# MCSPI2 register map
Vendor: Texas Instruments
Peripheral module from a debugger description file (folder omap34xx).
Registers are 32-bit, read-write, reset 0x0 unless marked. A register's access mark holds for its fields unless they carry their own. Offsets are as the file gives them; lines under a group give offsets from that group; [hi:lo] are bit positions; {n}, {i} and the like mark numbered series; 'fields as' and 'values as' point back to an identical list; <NAME> marks a mode.

## MCSPI2
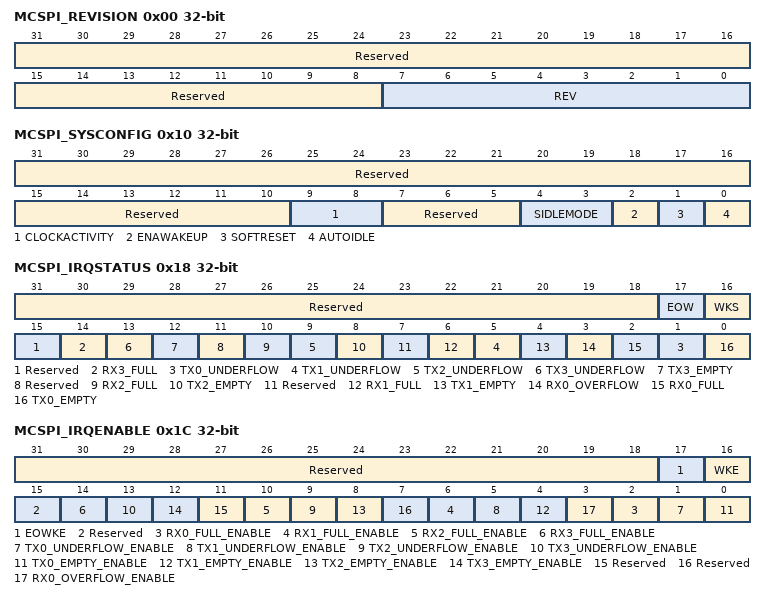
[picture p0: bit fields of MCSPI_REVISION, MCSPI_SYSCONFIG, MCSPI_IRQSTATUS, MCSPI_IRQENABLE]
0x00 MCSPI_REVISION ro (reset mask 0xFFFFFF00) — This register contains the hard coded RTL revision number.
  [31:8] Reserved — Reads returns 0
  [7:0] REV — IP revision[7:4] . Major revision . [3:0] . Minor revision . Example: 0x10 for 1.0, 0x21 for 2.1 .
0x10 MCSPI_SYSCONFIG — This register allows control of various parameters of the module interface. It is not sensitive to software reset.
  [31:10] Reserved — Reads returns 0
  [9:8] CLOCKACTIVITY — Clocks activity during wake up mode period
    0=Interface and Functional clocks may be switched off; 1=Interface clock is maintained. Functional clock may be switched off.; 2=Functional clock is maintained. Interface clock may be switched off.; 3=Interface and Functional clocks are maintained
  [7:5] Reserved — Reads returns 0
  [4:3] SIDLEMODE — Power management
    0=If an idle request is detected, the McSPI acknowledges it unconditionally and goes in Inactive mode. Interrupt, DMA requests and wake up lines are unconditionally de-asserted and the module wake-up capability is deactivated even if the bit[ ENAWAKEUP] is set.; 1=If an idle request is detected, the request is ignored and the module does not switch to wake up mode and keeps on behaving normally; 2=If an idle request is detected, the module will switch to wake up mode based on its internal activity and the wake up capability can be used if the bit[ENAWAKEUP] is set; 3=Reserved - do not use
  [2] ENAWAKEUP — Wake-up feature control
    0=Wake-up capability disabled; 1=Wake-up capability enabled
  [1] SOFTRESET — Software reset. Read always returns 0.
    0=Normal mode; 1=Trigger a module reset. This bit is automatically reset by hardware.
  [0] AUTOIDLE — Internal interface Clock gating strategy
    0=interface clock is free-running; 1=Automatic interface clock gating strategy is applied, based on the module interface activity
0x14 MCSPI_SYSSTATUS ro — This register provides status information about the module excluding the interrupt status information
  [0] RESETDONE — Internal Reset Monitoring
    0=Internal module reset is on-going; 1=Reset completed
0x18 MCSPI_IRQSTATUS — The interrupt status regroups all the status of the module internal events that can generate an interrupt
  [31:18] Reserved — Reads returns 0
  [17] EOW — End of word count event when a channel is enabled using the FIFO buffer and the channel had sent the number of SPI word defined by MCSPI_XFERLEVEL[31:16] WCNT bit field.
    0=EOW_0_w (Event status bit unchanged.); 0=EOW_0_r (Event false.); 1=EOW_1_w (Event status bit is reset.); 1=EOW_1_r (Event is pending.)
  [16] WKS — Wake-up event in slave mode when an active control signal is detected on the spim_csx line programmed in theMCSPI_CHxCONF[SPIENSLV] field (where x=0 only)
    0=WKS_0_w (Event status bit unchanged); 0=WKS_0_r (Event false); 1=WKS_1_w (Event status bit is reset.); 1=WKS_1_r (Event is pending.)
  [15] Reserved — Reads returns 0.
  [14] RX3_FULL — MCSPI_RX3 register is full (only when channel 3 is enabled)
    0=RX3_FULL_0_w (Event status bit unchanged); 0=RX3_FULL_0_r (Event false); 1=RX3_FULL_1_w (Event status bit is reset.); 1=RX3_FULL_1_r (Event is pending.)
  [4n+1] TX{n}_UNDERFLOW (n=0..3) — MCSPI_TX{n} register underflow (only when channel {n} is enabled)
    0=TX{n}_UNDERFLOW_0_w (Event status bit unchanged); 0=TX{n}_UNDERFLOW_0_r (Event false); 1=TX{n}_UNDERFLOW_1_w (Event status bit is reset.); 1=TX{n}_UNDERFLOW_1_r (Event is pending.)
  [12] TX3_EMPTY — MCSPI_TX3 register is empty (only when channel 3 is enabled)
    0=TX3_EMPTY_0_w (Event status bit unchanged); 0=TX3_EMPTY_0_r (Event false); 1=TX3_EMPTY_1_w (Event status bit is reset.); 1=TX3_EMPTY_1_r (Event is pending.)
  [11] Reserved — Read returns 0.
  [10] RX2_FULL — MCSPI_RX2 register full (only when channel 2 is enabled)
    0=RX2_FULL_0_w (Event status bit unchanged); 0=RX2_FULL_0_r (Event false); 1=RX2_FULL_1_w (Event status bit is reset.); 1=RX2_FULL_1_r (Event is pending.)
  [8] TX2_EMPTY — MCSPI_TX2 register empty (only when channel 2 is enabled)
    0=TX2_EMPTY_0_w (Event status bit unchanged); 0=TX2_EMPTY_0_r (Event false); 1=TX2_EMPTY_1_w (Event status bit is reset.); 1=TX2_EMPTY_1_r (Event is pending.)
  [7] Reserved — Read returns 0.
  [6] RX1_FULL — MCSPI_RX1 register full (only when channel 1 is enabled)
    0=RX1_FULL_0_w (Event status bit unchanged); 0=RX1_FULL_0_r (Event false); 1=RX1_FULL_1_w (Event status bit is reset.); 1=RX1_FULL_1_r (Event is pending.)
  [4] TX1_EMPTY — MCSPI_TX1 register empty (only when channel 1 is enabled)
    0=TX1_EMPTY_0_w (Event status bit unchanged); 0=TX1_EMPTY_0_r (Event false); 1=TX1_EMPTY_1_w (Event status bit is reset.); 1=TX1_EMPTY_1_r (Event is pending.)
  [3] RX0_OVERFLOW — MCSPI_RX0 register overflow (only in slave mode)
    0=RX0_OVERFLOW_0_w (Event status bit unchanged); 0=RX0_OVERFLOW_0_r (Event false); 1=RX0_OVERFLOW_1_w (Event status bit is reset.); 1=RX0_OVERFLOW_1_r (Event is pending.)
  [2] RX0_FULL — MCSPI_RX0 register full (only when channel 0 is enabled)
    0=RX0_FULL_0_w (Event status bit unchanged); 0=RX0_FULL_0_r (Event false); 1=RX0_FULL_1_w (Event status bit is reset.); 1=RX0_FULL_1_r (Event is pending.)
  [0] TX0_EMPTY — MCSPI_TX0 register empty (only when channel 0 is enabled)
    0=TX0_EMPTY_0_w (Event status bit unchanged); 0=TX0_EMPTY_0_r (Event false); 1=TX0_EMPTY_1_w (Event status bit is reset.); 1=TX0_EMPTY_1_r (Event is pending.)
0x1C MCSPI_IRQENABLE — This register allows to enable/disable the module internal sources of interrupt, on an event-by-event basis.
  [31:18] Reserved — Reads return 0
  [17] EOWKE — End of Word count Interrupt Enable.
    0=Interrupt disabled; 1=Interrupt enabled
  [16] WKE — Wake-up event interrupt enable in slave mode when an active control signal is detected on the spim_csx line programmed in theMCSPI_CHxCONF[SPIENSLV] field (where x=0 only)
    0=Interrupt disabled; 1=Interrupt enabled
  [15] Reserved — Read returns 0.
  [4n+2] RX{n}_FULL_ENABLE (n=0..3) — MCSPI_RX{n} register full interrupt enable (channel {n})
    0=Interrupt disabled; 1=Interrupt enabled
  [4n+1] TX{n}_UNDERFLOW_ENABLE (n=0..3) — MCSPI_TX{n} register underflow interrupt enable (channel {n})
    0=Interrupt disabled; 1=Interrupt enabled
  [4n] TX{n}_EMPTY_ENABLE (n=0..3) — MCSPI_TX{n} register empty interrupt enable (channel {n})
    0=Interrupt disabled; 1=Interrupt enabled
  [11] Reserved — Read returns 0.
  [7] Reserved — Read returns 0.
  [3] RX0_OVERFLOW_ENABLE — MCSPI_RX0 register overflow interrupt enable (channel 0)
    0=Interrupt disabled; 1=Interrupt enabled
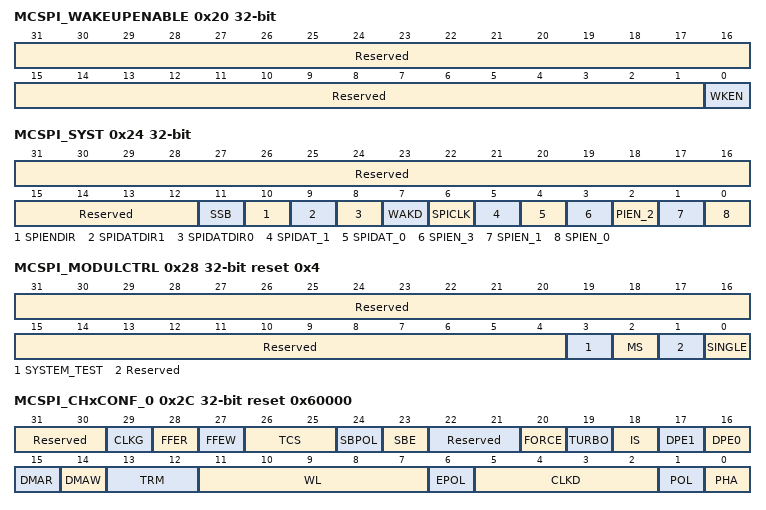
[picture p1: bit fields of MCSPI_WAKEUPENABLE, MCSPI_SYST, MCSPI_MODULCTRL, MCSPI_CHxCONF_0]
0x20 MCSPI_WAKEUPENABLE — The wake-up enable register allows to enable/disable the module internal sources of wake-up on event-by-event basis.
  [31:1] Reserved — Reads return 0
  [0] WKEN — Wake-up functionality in slave mode when an active control signal is detected on the spim_cs line programmed in the fieldMCSPI_CHxCONF[SPIENSLV]
    0=The event is not allowed to wake-up the system, even if the global control bit MCSPI_SYSCONF[ENAWAKEUP] is set; 1=The event is allowed to wake-up the system if the global control bit MCSPI_SYSCONF[ENAWAKEUP] is set
0x24 MCSPI_SYST — This register is used to check the correctness of the system interconnect either internally to peripheral bus, or externally to device IO pads, when the module is configured in system test (SYSTEST) mode.
  [31:12] Reserved — Reads returns 0
  [11] SSB — Set status bitThis bit must be cleared prior attempting to clear a status bit of the MCSPI_ IRQSTATUS register. . Writing 1 into this bit sets to 1 all status bits contained in the register. .
    0=No action. Writing 0 does not clear already set status bits;; 1=Force to 1 all status bits of MCSPI_ IRQSTATUS register
  [10] SPIENDIR — Set the direction of the spim_cs lines and spim_clk line
    0=Output (as in master mode); 1=Input (as in slave mode)
  [9] SPIDATDIR1 — Set the direction of the SPIDAT[1] (spim_simo)
    0=Output; 1=Input
  [8] SPIDATDIR0 — Set the direction of the SPIDAT[0] (spim_somi)
    0=Output; 1=Input
  [7] WAKD — SWAKEUP output (signal data value of internal signal to system).The signal is driven high or low according to the value written into this register bit. .
    0=The pin is driven low; 1=The pin is driven high
  [6] SPICLK — spim_clk line (signal data value)If[SPIENDIR] = 1 (input mode direction), this bit returns the value on the spim_clk line (high or low) and a write into this bit has no effect. . If[SPIENDIR] = 0 (output mode direction), the spim_clk line is driven high or low according to the value written into this register. .
  [5] SPIDAT_1 — spim_somi line (signal data value)If[SPIDATDIR1] = 0 (output mode direction), the spim_somi line is driven high or low according to the value written into this register. . If[SPIDATDIR1] = 1 (input mode direction), this bit returns the value on the spim_somi line (high or low) and a write into this bit has no effect. .
  [4] SPIDAT_0 — spim_simo line (signal data value)If[SPIDATDIR0] = 0 (output mode direction), the spim_simo line is driven high or low according to the value written into this register. . If[SPIDATDIR0] = 1 (input mode direction), this bit returns the value on the spim_simo line (high or low) and a write into this bit has no effect. .
  [3] SPIEN_3 — spim_cs3 line (signal data value)If[SPIENDIR] = 0 (output mode direction), the spim_cs3 line is driven high or low according to the value written into this register. . If[SPIENDIR] = 1 (input mode direction), this bit returns the value on the spim_cs3 line (high or low) and a write into this bit has no effect. .
  [2] PIEN_2 — spim_cs2 line (signal data value)If[SPIENDIR] = 0 (output mode direction), the spim_cs2 line is driven high or low according to the value written into this register. . If[SPIENDIR] = 1 (input mode direction), this bit returns the value on the spim_cs2 line (high or low) and a write into this bit has no effect. .
  [1] SPIEN_1 — spim_cs1 line (signal data value)If[SPIENDIR] = 0 (output mode direction), the spim_cs1 line is driven high or low according to the value written into this register. . If[SPIENDIR] = 1 (input mode direction), this bit returns the value on the spim_cs1 line (high or low) and a write into this bit has no effect. .
  [0] SPIEN_0 — spim_cs0 line (signal data value)If[SPIENDIR] = 0 (output mode direction), the spim_cs0 line is driven high or low according to the value written into this register. . If[SPIENDIR] = 1 (input mode direction), this bit returns the value on the spim_cs0 line (high or low) and a write into this bit has no effect. .
0x28 MCSPI_MODULCTRL reset 0x4 — This register is dedicated to the configuration of the serial port interface.
  [31:4] Reserved — Reads returns 0
  [3] SYSTEM_TEST — Enables the system test mode
    0=Functional mode; 1=System test mode (SYSTEST)
  [2] MS — Master/ Slave
    0=Master - The module generates the spim_clk and spim_cs for channel x; 1=Slave - The module receive
  [1] Reserved — (returns 0 after writing 0) (returns 1 after writing 1)
  [0] SINGLE — Single forced channel/multichannel (master mode only)
    0=One or more channels will be used in master mode with automatic chip-select generation; 1=Only one channel will be used in master mode and the chip-select is driven by the[20] FORCE bit. This bit must be set in force spim_cs mode.
0x2C MCSPI_CHxCONF_0 reset 0x60000 — This register is dedicated to the configuration of the channel x.
  [31:30] Reserved — Read returns 0s.
  [29] CLKG — Clock divider granularity. This register defines the granularity of channel clock divider: power of two or one clock cycle granularity. When this bit is set, theMCSPI_CHxCTRL[15:8] EXTCLK bit field must be configured to reach a maximum of 4096 clock divider ratio. Then the clock divider ratio is a concatenation of MCSPI_CHxCONF[5:2] CLKD and EXTCLK values.
    0=Clock granularity of power of two; 1=One clock cycle ganularity
  [28] FFER — FIFO enabled for Receive. Only one channel can have this bit field set.
    0=The buffer is not used to Receive data; 1=The buffer is used to Receive data
  [27] FFEW — FIFO enabled for Transmit. Only one channel can have this bit field set.
    0=The buffer is not used to Transmit data; 1=The buffer is used to Transmit data
  [26:25] TCS — Chip select time controlDefines the number of interface clock cycles between CS toggling and first (or last) edge of SPI clock. .
    0=0.5 clock cycle; 1=1.5 clock cycles; 2=2.5 clock cycles; 3=3.5 clock cycles
  [24] SBPOL — Start bit polarity
    0=Start bit polarity is held to 0 during SPI transfer; 1=Start bit polarity is held to 1 during SPI transfer
  [23] SBE — Start bit enable for SPI transfer
    0=Default SPI transfer length as specified by WL bit field; 1=Start bit D/CX added before SPI transfer. Polarity is defined by[SBPOL].
  [22:21] Reserved — Write the reset value. Read returns the reset value.
  [20] FORCE — Manual spim_csx assertion to keep spim_csx for channel x active between SPI words (single channel master mode only). TheMCSPI_MODULCTRL[0] SINGLE bit must bit set to 1.
    0=Writing 0 into this bit drives the spin_csx line low for channel x when [6] EPOL = 0, and drives it high when [6] EPOL = 1; 1=Writing 1 into this bit drives the spim_csx line high for channel x when[E6] EPOL = 0, and drives it low when [6] EPOL = 1
  [19] TURBO — Turbo mode
    0=Turbo is deactivated (recommended for single SPI word transfer); 1=Turbo is activated to maximize the throughput for multi-SPI word transfers
  [18] IS — Input select
    0=Data Line 0 (spim_somi) selected for reception; 1=Data Line 1 (spim_simo) selected for reception
  [17] DPE1 — Transmission enable for data line 1 (spim_simo)
    0=Data Line 1 (spim_simo) selected for transmission; 1=No transmission on data Line 1 (spim_simo)
  [16] DPE0 — Transmission enable for data line 0 (spim_somi)
    0=Data Line 0 (spim_somi) selected for transmission; 1=No transmission on data Line 0 (spim_somi)
  [15] DMAR — DMA Read requestThe DMA Read request line is asserted when the channel is enabled and a new data is available in the receive register of the channel. . The DMA Read request line is deasserted on read completion of the receive register of the channel. .
    0=DMA read request disabled; 1=DMA read request enabled
  [14] DMAW — DMA Write request.The DMA write request line is asserted when the channel is enabled and the register of the channel is empty. . The DMA write request line is deasserted on load completion of the register of the channel. .
    0=DMA write request disabled; 1=DMA write request enabled
  [13:12] TRM — Transmit/receive modes
    0=Transmit and receive mode; 1=Receive-only mode; 2=Transmit-only mode
  [11:7] WL — SPI word length
    {v}=The SPI word is {v+1}-bit long (v=3..31)
  [6] EPOL — spim_csx polarity for channel x
    0=spim_csx is held high during the active state; 1=spim_csx is held low during the active state
  [5:2] CLKD — Frequency divider for spim_clk (for master device only)
    0=1; 1=2; 2=4; 3=8; 4=16; 5=32; 6=64; 7=128; 8=256; 9=512; 10=1024; 11=2048; 12=4096; 13=8192; 14=16384; 15=32768
  [1] POL — spim_clk polarity
    0=spim_clk is held high during the active state; 1=spim_clk is held low during the active state
  [0] PHA — spim_clk phase
    0=Data are latched on odd-numbered edges of spim_clk; 1=Data are latched on even-numbered edges of spim_clk
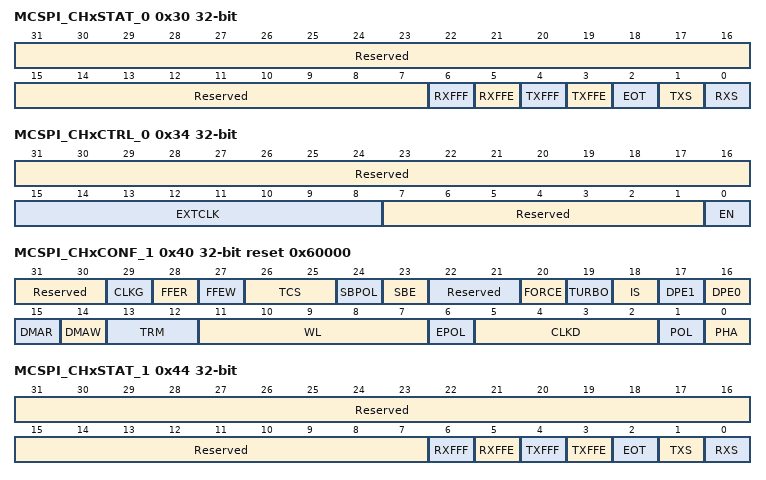
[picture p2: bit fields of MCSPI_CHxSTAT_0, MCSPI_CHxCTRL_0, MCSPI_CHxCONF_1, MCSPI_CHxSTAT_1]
0x30 MCSPI_CHxSTAT_0 ro — This register provides status information about and registers of channel x.
  [31:7] Reserved — Read returns 0s.
  [6] RXFFF — Channel x FIFO Receive Buffer Full Status
    0=RXFFF_0_r (FIFO Receive Buffer is not full); 1=RXFFF_1_r (FIFO Receive Buffer is full)
  [5] RXFFE — Channel x FIFO Receive Buffer Empty Status
    0=RXFFE_0_r (FIFO Receive Buffer is not empty); 1=RXFFE_1_r (FIFO Receive Buffer is empty)
  [4] TXFFF — Channel x FIFO Transmit Buffer Full Status
    0=TXFFF_0_r (FIFO Transmit Buffer is not full); 1=TXFFF_1_r (FIFO Transmit Buffer is full)
  [3] TXFFE — Channel x FIFO Transmit Buffer Empty Status
    0=TXFFE_0_r (FIFO Transmit Buffer is not empty); 1=TXFFE_1_r (FIFO Transmit Buffer is empty)
  [2] EOT — Channel x end-of-transfer status. The definitions of beginning and end of transfer vary with master versus slave and the transfer format (transmit/receive mode, turbo mode). See dedicated chapters for details.
    0=EOT_0_r (This flag is automatically cleared when the shift register is loaded with the data from the register (beginning of transfer).); 1=EOT_1_r (This flag is automatically set to one at the end of an SPI transfer.)
  [1] TXS — Channel xMCSPI_TXx register status
    0=TXS_0_r (Register is full.); 1=TXS_1_r (Register is empty.)
  [0] RXS — Channel xMCSPI_RXx register status
    0=RXS_0_r (Register is empty.); 1=RXS_1_r (Register is full.)
0x34 MCSPI_CHxCTRL_0 — This register is dedicated to enable the channel x
  [31:16] Reserved — Read returns 0s.
  [15:8] EXTCLK — Clock ratio extension: This register is used to concatenate withMCSPI_CHxCONF[5:2] CLKD bit field for clock ratio only when granularity is one clock cycle (MCSPI_CHxCONF[28] CLKG bit set to 1). Then the max value reached is 4096 clock divider ratio.
    0=Clock ratio is CLKD + 1; 1=Clock ratio is CLKD + 1 + 16; 255=Clock ratio is CLKD + 1 + 4080
  [7:1] Reserved — Read returns 0s.
  [0] EN — Channel enable
    0=Channel x is not active; 1=Channel x is active
0x38 MCSPI_TXx_0 — This register contains a single SPI word to transmit on the serial link, whatever SPI word length is.
  [31:0] TDATA — Channel 0 Data to transmit
0x3C MCSPI_RXx_0 ro — This register contains a single SPI word received through the serial link, what ever SPI word length is.
  [31:0] RDATA — Channel 0 Received Data
0x40 MCSPI_CHxCONF_1 reset 0x60000 — This register is dedicated to the configuration of the channel x.
  fields as MCSPI_CHxCONF_0
0x44 MCSPI_CHxSTAT_1 ro — This register provides status information about and registers of channel x.
  fields as MCSPI_CHxSTAT_0
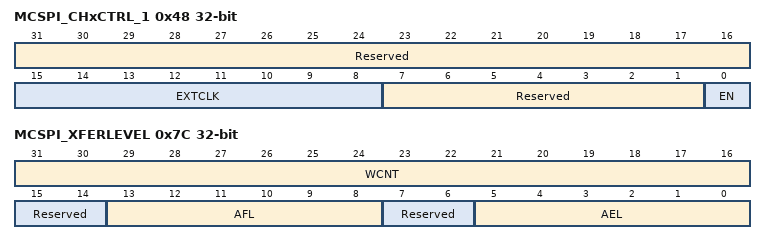
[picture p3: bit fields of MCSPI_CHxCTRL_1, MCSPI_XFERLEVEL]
0x48 MCSPI_CHxCTRL_1 — This register is dedicated to enable the channel x
  fields as MCSPI_CHxCTRL_0
0x4C MCSPI_TXx_1 — This register contains a single SPI word to transmit on the serial link, whatever SPI word length is.
  [31:0] TDATA — Channel 0 Data to transmit
0x50 MCSPI_RXx_1 ro — This register contains a single SPI word received through the serial link, what ever SPI word length is.
  [31:0] RDATA — Channel 0 Received Data
0x7C MCSPI_XFERLEVEL — This register provides transfer levels needed while using FIFO buffer during transfer.
  [31:16] WCNT — Spi word counter: This register holds the programmable value of number of SPI word to be transferred on channel which is using the FIFO buffer. When transfer had started, a read back in this register returns the current SPI word transfer index.
    0=Counter not used; 1=One spi word; 0xFFFE=65534 spi word; 0xFFFF=65535 spi word
  [15:14] Reserved — Read returns 0s.
  [13:8] AFL — Buffer Almost Full: This register holds the programmable almost full level value used to determine almost full buffer condition. If the user wants an interrupt or a DMA read request to be issued during a receive operation when the data buffer holds at least I bytes, then this bit field must be set to I-1.
    0=One byte; 1=2 bytes; 62=63 bytes; 63=64 bytes
  [7:6] Reserved — Read returns 0s.
  [5:0] AEL — Buffer Almost Empty: This register holds the programmable almost empty level value used to determine almost empty buffer condition. If the user wants an interrupt or a DMA write request to be issued during a transmit operation when the data buffer is able to receive I bytes, then this bit field must be set to I-1.
    0=One byte; 1=2 bytes; 62=63 bytes; 63=64 bytes
